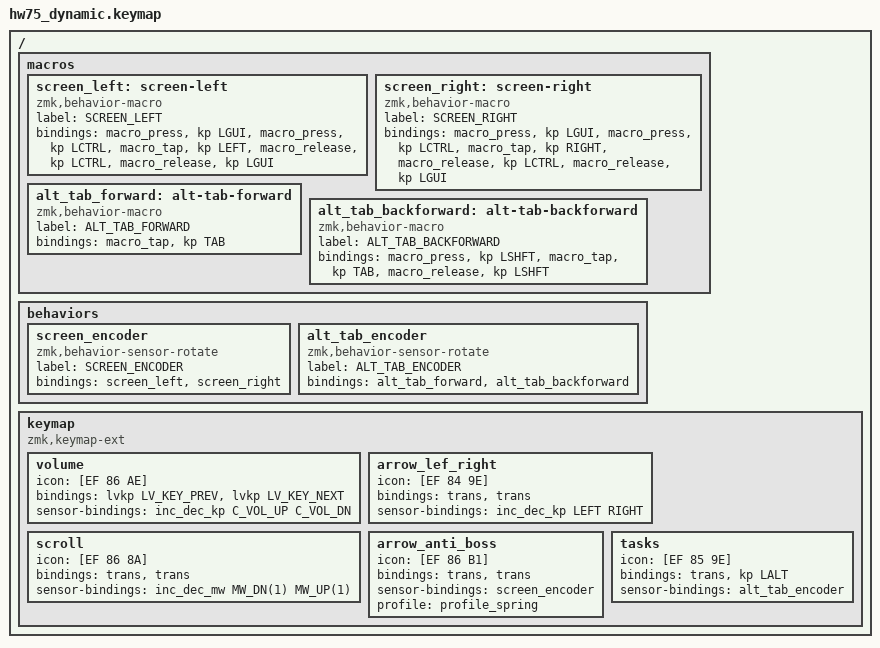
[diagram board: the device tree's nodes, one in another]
/*
 * Copyright (c) 2022 The ZMK Contributors
 * SPDX-License-Identifier: MIT
 */

#include <behaviors.dtsi>
#include <behaviors/lvgl_key_press.dtsi>
#include <behaviors/sensor_rotate_mouse_wheel.dtsi>
#include <dt-bindings/zmk/keys.h>
#include <dt-bindings/zmk/rgb.h>
#include <dt-bindings/zmk/lvgl.h>
#include <dt-bindings/zmk/mouse.h>

/ {
	macros {
		screen_left: screen-left {
			label = "SCREEN_LEFT";
			compatible = "zmk,behavior-macro";
			#binding-cells = <0>;
			bindings =
				<&macro_press   &kp LGUI>,
                <&macro_press   &kp LCTRL>,
				<&macro_tap     &kp LEFT>,
                <&macro_release &kp LCTRL>,
				<&macro_release &kp LGUI>;
		};

		screen_right: screen-right {
			label = "SCREEN_RIGHT";
			compatible = "zmk,behavior-macro";
			#binding-cells = <0>;
			bindings =
				<&macro_press   &kp LGUI>,
                <&macro_press   &kp LCTRL>,
				<&macro_tap     &kp RIGHT>,
                <&macro_release &kp LCTRL>,
				<&macro_release &kp LGUI>;
		};

		alt_tab_forward: alt-tab-forward {
			label = "ALT_TAB_FORWARD";
			compatible = "zmk,behavior-macro";
			#binding-cells = <0>;
			bindings =
				<&macro_tap     &kp TAB>;
		};

		alt_tab_backforward: alt-tab-backforward {
			label = "ALT_TAB_BACKFORWARD";
			compatible = "zmk,behavior-macro";
			#binding-cells = <0>;
			bindings =
				<&macro_press   &kp LSHFT>,
				<&macro_tap     &kp TAB>,
				<&macro_release &kp LSHFT>;
		};
	};

    behaviors {
        screen_encoder: screen_encoder {
            compatible = "zmk,behavior-sensor-rotate";
            label = "SCREEN_ENCODER";
            #sensor-binding-cells = <0>;
            bindings = <&screen_left>, <&screen_right>;
        };

		alt_tab_encoder: alt_tab_encoder {
            compatible = "zmk,behavior-sensor-rotate";
            label = "ALT_TAB_ENCODER";
            #sensor-binding-cells = <0>;
            bindings = <&alt_tab_forward>, <&alt_tab_backforward>;
        };
    };

	keymap {
		compatible = "zmk,keymap-ext", "zmk,keymap";

		volume {
			label = "音量";
			icon = [EF 86 AE];
			bindings = <&lvkp LV_KEY_PREV &lvkp LV_KEY_NEXT>;
			sensor-bindings = <&inc_dec_kp C_VOL_UP C_VOL_DN>;
		};

		arrow_lef_right {
			label = "快进";
			icon = [EF 84 9E];
			bindings = <&trans &trans>;
			sensor-bindings = <&inc_dec_kp LEFT RIGHT>;
		};
        
		scroll {
			label = "滚动";
			icon = [EF 86 8A];
			bindings = <&trans &trans>;
			sensor-bindings = <&inc_dec_mw MW_DN(1) MW_UP(1)>;
		};

		arrow_anti_boss {
			label = "切换";
			icon = [EF 86 B1];
			bindings = <&trans &trans>;
			sensor-bindings = <&screen_encoder>;
            profile = <&profile_spring>;
		};

        tasks {
            label = "窗口";
            icon = [EF 85 9E];
            bindings = <&trans &kp LALT>;
            sensor-bindings = <&alt_tab_encoder>;
		};
	};
};
